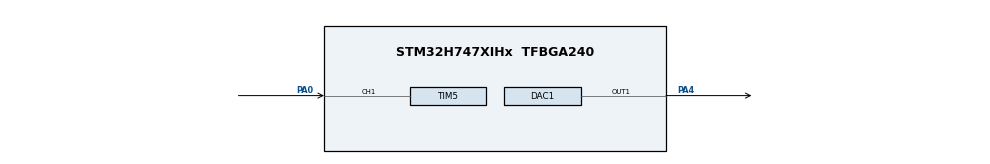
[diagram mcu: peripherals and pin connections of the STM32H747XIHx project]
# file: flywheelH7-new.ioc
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CortexM4.IPs=BDMA,CORTEX_M4\:I,DEBUG,DMA,FATFS_M4\:I,FREERTOS_M4\:I,GPIO,IWDG2\:I,MDMA,NVIC2\:I,OPENAMP_M4\:I,PDM2PCM_M4\:I,PWR,RCC,RESMGR_UTILITY,SYS_M4\:I,USB_DEVICE_M4\:I,USB_HOST_M4\:I,VREFBUF,WWDG2\:I
CortexM7.IPs=BDMA\:I,CORTEX_M7\:I,DEBUG\:I,DMA\:I,FATFS_M7\:I,FREERTOS_M7\:I,GPIO\:I,IWDG1\:I,MDMA\:I,NVIC1\:I,OPENAMP_M7\:I,PDM2PCM_M7\:I,PWR\:I,RCC\:I,RESMGR_UTILITY\:I,SYS\:I,USB_DEVICE_M7\:I,USB_HOST_M7\:I,VREFBUF\:I,WWDG1\:I,DAC1\:I,TIM2\:I,TIM5\:I
DAC1.DAC_Channel-DAC_OUT1=DAC_CHANNEL_1
Mcu.Family=STM32H7
Mcu.Name=STM32H747XIHx
Mcu.Package=TFBGA240
NVIC1.PriorityGroup=NVIC_PRIORITYGROUP_4
NVIC1.TIM5_IRQn=true\:0\:0\:false\:false\:true\:true\:true\:true
NVIC2.PriorityGroup=NVIC_PRIORITYGROUP_4
PA0.PinAttribute=CortexM7
PA0.Signal=S_TIM5_CH1
PA4.PinAttribute=CortexM7
PA4.Signal=COMP_DAC11_group
PH0-OSC_IN\ (PH0).Mode=HSE-External-Oscillator
PH0-OSC_IN\ (PH0).PinAttribute=Free
PH0-OSC_IN\ (PH0).Signal=RCC_OSC_IN
PH1-OSC_OUT\ (PH1).Mode=HSE-External-Oscillator
PH1-OSC_OUT\ (PH1).PinAttribute=Free
PH1-OSC_OUT\ (PH1).Signal=RCC_OSC_OUT
ProjectManager.HeapSize=M4-0x200,M7-0x200
ProjectManager.StackSize=M4-0x400,M7-0x400
ProjectManager.TargetToolchain=STM32CubeIDE
RCC.ADCFreq_Value=50390625
RCC.APB1Freq_Value=100000000
RCC.APB2Freq_Value=100000000
RCC.APB3Freq_Value=100000000
RCC.APB4Freq_Value=100000000
RCC.CortexFreq_Value=400000000
RCC.D1PPRE=RCC_APB3_DIV2
RCC.D2PPRE1=RCC_APB1_DIV2
RCC.D2PPRE2=RCC_APB2_DIV2
RCC.D3PPRE=RCC_APB4_DIV2
RCC.DIVM1=2
RCC.DIVN1=64
RCC.HCLKFreq_Value=200000000
RCC.HPRE=RCC_HCLK_DIV2
RCC.PLL2FRACN=0
RCC.PLL3FRACN=0
RCC.PLLFRACN=0
RCC.PLLSourceVirtual=RCC_PLLSOURCE_HSE
RCC.SYSCLKFreq_VALUE=400000000
RCC.SYSCLKSource=RCC_SYSCLKSOURCE_PLLCLK
RCC.USART16CLockSelection=RCC_USART16CLKSOURCE_CSI
RCC.USBCLockSelection=RCC_USBCLKSOURCE_HSI48
RCC.USBFreq_Value=48000000
SH.COMP_DAC11_group.0=DAC1_OUT1,DAC_OUT1
SH.S_TIM5_CH1.0=TIM5_CH1,Input_Capture1_from_TI1
SYS.userName=SYS_M7
TIM5.Channel-Input_Capture1_from_TI1=TIM_CHANNEL_1
VP_SYS_M4_VS_Systick.Mode=SysTick
VP_TIM2_VS_ClockSourceINT.Mode=Internal
VP_TIM5_VS_ClockSourceINT.Mode=Internal
board=custom

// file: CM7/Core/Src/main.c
/* USER CODE BEGIN Header */
/**
  ******************************************************************************
  * @file           : main.c
  * @brief          : Main program body
  ******************************************************************************
  * @attention
  *
  * Copyright (c) 2023 STMicroelectronics.
  * All rights reserved.
  *
  * This software is licensed under terms that can be found in the LICENSE file
  * in the root directory of this software component.
  * If no LICENSE file comes with this software, it is provided AS-IS.
  *
  ******************************************************************************
  */
/* USER CODE END Header */
#include "main.h"

/* USER CODE BEGIN Includes */
#include <stdio.h>
#include <math.h>
#include<arm_math.h>
//#include "retarget.h"

/* USER CODE END Includes */

/* USER CODE BEGIN PD */

#ifndef HSEM_ID_0
#define HSEM_ID_0 (0U) /* HW semaphore 0*/
#endif
/* USER CODE END PD */

DAC_HandleTypeDef hdac1;

TIM_HandleTypeDef htim2;
TIM_HandleTypeDef htim5;

/* USER CODE BEGIN PV */
#define FFT_BUFFER_SIZE 256
#define SAMPLE_SIZE 113
#define NUM_FIRINGS 3

struct Result {
	float amplitude;
	float phase;
};

uint8_t done1 = 0;
uint8_t revs = 0;

float radians [SAMPLE_SIZE]; //changed from 258 to 129

float freq = 0;

float phase_data[200];

uint8_t phase_index = 0;

float timee2 = 0;

float radianAvg = 0;

float third_harmonic_ampl = 0;

float third_harmonic_phase = 0;

struct Result results;

//float resultantAngularAcc = 0;
//float total = 0;
//float radianAvg;
//float rate;

arm_rfft_fast_instance_f32 fftHandler;

float fftBufIn[FFT_BUFFER_SIZE];
float fftBufOut[FFT_BUFFER_SIZE];

float fftResult[FFT_BUFFER_SIZE/2];

//char radianStr[9];
/* USER CODE END PV */

void SystemClock_Config(void);
static void MX_GPIO_Init(void);
static void MX_DAC1_Init(void);
static void MX_TIM2_Init(void);
static void MX_TIM5_Init(void);
/* USER CODE BEGIN PFP */

struct Result fftCalc(float rad[SAMPLE_SIZE]);

uint16_t dacOut(float out);
/* USER CODE END PFP */

int main(void)
{
/* USER CODE BEGIN Boot_Mode_Sequence_0 */
  int32_t timeout;
/* USER CODE END Boot_Mode_Sequence_0 */

  /* Enable I-Cache---------------------------------------------------------*/
  SCB_EnableICache();

  /* Enable D-Cache---------------------------------------------------------*/
  SCB_EnableDCache();

/* USER CODE BEGIN Boot_Mode_Sequence_1 */
  /* Wait until CPU2 boots and enters in stop mode or timeout*/

  timeout = 0xFFFF;
 while((__HAL_RCC_GET_FLAG(RCC_FLAG_D2CKRDY) != RESET) && (timeout-- > 0));
 if ( timeout < 0 )
 {
 Error_Handler();
 }

/* USER CODE END Boot_Mode_Sequence_1 */
  /* MCU Configuration--------------------------------------------------------*/

  /* Reset of all peripherals, Initializes the Flash interface and the Systick. */
  HAL_Init();

  /* Configure the system clock */
  SystemClock_Config();
/* USER CODE BEGIN Boot_Mode_Sequence_2 */
/* When system initialization is finished, Cortex-M7 will release Cortex-M4 by means of
HSEM notification */
/*HW semaphore Clock enable*/
__HAL_RCC_HSEM_CLK_ENABLE();
/*Take HSEM */
HAL_HSEM_FastTake(HSEM_ID_0);
/*Release HSEM in order to notify the CPU2(CM4)*/
HAL_HSEM_Release(HSEM_ID_0,0);
/* wait until CPU2 wakes up from stop mode */
timeout = 0xFFFF;
while((__HAL_RCC_GET_FLAG(RCC_FLAG_D2CKRDY) == RESET) && (timeout-- > 0));
if ( timeout < 0 )
{
Error_Handler();
}
/* USER CODE END Boot_Mode_Sequence_2 */

  /* Initialize all configured peripherals */
  MX_GPIO_Init();
  MX_DAC1_Init();
  MX_TIM2_Init();
  MX_TIM5_Init();
  /* USER CODE BEGIN 2 */
  arm_rfft_fast_init_f32(&fftHandler, FFT_BUFFER_SIZE);
HAL_DAC_Start(&hdac1,DAC_CHANNEL_1);
  HAL_DAC_SetValue(&hdac1, DAC_CHANNEL_1,DAC_ALIGN_12B_R,0);
  TIM5->CNT = 0;
  HAL_TIM_IC_Start_IT(&htim5, TIM_CHANNEL_1);
    TIM2->CNT = 0;
  HAL_TIM_Base_Start(&htim2);

  //printf("start");

  /* USER CODE END 2 */

  /* Infinite loop */
  /* USER CODE BEGIN WHILE */
  while (1)
  {

    if(done1 ==1){

      TIM2->CNT = 0;

      struct Result results = fftCalc(radians);

      timee2 = TIM2->CNT/200;
      third_harmonic_ampl = results.amplitude;

      third_harmonic_phase = results.phase;

      revs = revs + 1;

//      phase_data[phase_index] = third_harmonic_phase;
      uint16_t finalOut = dacOut(results.amplitude);

//      phase_index = phase_index + 1;
//      TIM2->CNT = 0;

      done1 = 0;

    //TIM5->CNT = 0;//Resets counter

    //HAL_TIM_IC_Start_IT(&htim5, TIM_CHANNEL_1);
    }
    /* USER CODE END WHILE */

  }
}

void SystemClock_Config(void)
{
  RCC_OscInitTypeDef RCC_OscInitStruct = {0};
  RCC_ClkInitTypeDef RCC_ClkInitStruct = {0};

  /** Supply configuration update enable
  */
  HAL_PWREx_ConfigSupply(PWR_DIRECT_SMPS_SUPPLY);

  /** Configure the main internal regulator output voltage
  */
  __HAL_PWR_VOLTAGESCALING_CONFIG(PWR_REGULATOR_VOLTAGE_SCALE1);

  while(!__HAL_PWR_GET_FLAG(PWR_FLAG_VOSRDY)) {}

  /** Initializes the RCC Oscillators according to the specified parameters
  * in the RCC_OscInitTypeDef structure.
  */
  RCC_OscInitStruct.OscillatorType = RCC_OSCILLATORTYPE_HSE;
  RCC_OscInitStruct.HSEState = RCC_HSE_ON;
  RCC_OscInitStruct.PLL.PLLState = RCC_PLL_ON;
  RCC_OscInitStruct.PLL.PLLSource = RCC_PLLSOURCE_HSE;
  RCC_OscInitStruct.PLL.PLLM = 2;
  RCC_OscInitStruct.PLL.PLLN = 64;
  RCC_OscInitStruct.PLL.PLLP = 2;
  RCC_OscInitStruct.PLL.PLLQ = 2;
  RCC_OscInitStruct.PLL.PLLR = 2;
  RCC_OscInitStruct.PLL.PLLRGE = RCC_PLL1VCIRANGE_3;
  RCC_OscInitStruct.PLL.PLLVCOSEL = RCC_PLL1VCOWIDE;
  RCC_OscInitStruct.PLL.PLLFRACN = 0;
  if (HAL_RCC_OscConfig(&RCC_OscInitStruct) != HAL_OK)
  {
    Error_Handler();
  }

  /** Initializes the CPU, AHB and APB buses clocks
  */
  RCC_ClkInitStruct.ClockType = RCC_CLOCKTYPE_HCLK|RCC_CLOCKTYPE_SYSCLK
                              |RCC_CLOCKTYPE_PCLK1|RCC_CLOCKTYPE_PCLK2
                              |RCC_CLOCKTYPE_D3PCLK1|RCC_CLOCKTYPE_D1PCLK1;
  RCC_ClkInitStruct.SYSCLKSource = RCC_SYSCLKSOURCE_PLLCLK;
  RCC_ClkInitStruct.SYSCLKDivider = RCC_SYSCLK_DIV1;
  RCC_ClkInitStruct.AHBCLKDivider = RCC_HCLK_DIV2;
  RCC_ClkInitStruct.APB3CLKDivider = RCC_APB3_DIV2;
  RCC_ClkInitStruct.APB1CLKDivider = RCC_APB1_DIV2;
  RCC_ClkInitStruct.APB2CLKDivider = RCC_APB2_DIV2;
  RCC_ClkInitStruct.APB4CLKDivider = RCC_APB4_DIV2;

  if (HAL_RCC_ClockConfig(&RCC_ClkInitStruct, FLASH_LATENCY_2) != HAL_OK)
  {
    Error_Handler();
  }
}

static void MX_DAC1_Init(void)
{

  DAC_ChannelConfTypeDef sConfig = {0};

  /** DAC Initialization
  */
  hdac1.Instance = DAC1;
  if (HAL_DAC_Init(&hdac1) != HAL_OK)
  {
    Error_Handler();
  }

  /** DAC channel OUT1 config
  */
  sConfig.DAC_SampleAndHold = DAC_SAMPLEANDHOLD_DISABLE;
  sConfig.DAC_Trigger = DAC_TRIGGER_NONE;
  sConfig.DAC_OutputBuffer = DAC_OUTPUTBUFFER_ENABLE;
  sConfig.DAC_ConnectOnChipPeripheral = DAC_CHIPCONNECT_DISABLE;
  sConfig.DAC_UserTrimming = DAC_TRIMMING_FACTORY;
  if (HAL_DAC_ConfigChannel(&hdac1, &sConfig, DAC_CHANNEL_1) != HAL_OK)
  {
    Error_Handler();
  }

}

static void MX_TIM2_Init(void)
{

  TIM_ClockConfigTypeDef sClockSourceConfig = {0};
  TIM_MasterConfigTypeDef sMasterConfig = {0};

  htim2.Instance = TIM2;
  htim2.Init.Prescaler = 0;
  htim2.Init.CounterMode = TIM_COUNTERMODE_UP;
  htim2.Init.Period = 4294967295;
  htim2.Init.ClockDivision = TIM_CLOCKDIVISION_DIV1;
  htim2.Init.AutoReloadPreload = TIM_AUTORELOAD_PRELOAD_DISABLE;
  if (HAL_TIM_Base_Init(&htim2) != HAL_OK)
  {
    Error_Handler();
  }
  sClockSourceConfig.ClockSource = TIM_CLOCKSOURCE_INTERNAL;
  if (HAL_TIM_ConfigClockSource(&htim2, &sClockSourceConfig) != HAL_OK)
  {
    Error_Handler();
  }
  sMasterConfig.MasterOutputTrigger = TIM_TRGO_RESET;
  sMasterConfig.MasterSlaveMode = TIM_MASTERSLAVEMODE_DISABLE;
  if (HAL_TIMEx_MasterConfigSynchronization(&htim2, &sMasterConfig) != HAL_OK)
  {
    Error_Handler();
  }

}

static void MX_TIM5_Init(void)
{

  TIM_ClockConfigTypeDef sClockSourceConfig = {0};
  TIM_MasterConfigTypeDef sMasterConfig = {0};
  TIM_IC_InitTypeDef sConfigIC = {0};

  htim5.Instance = TIM5;
  htim5.Init.Prescaler = 0;
  htim5.Init.CounterMode = TIM_COUNTERMODE_UP;
  htim5.Init.Period = 4294967295;
  htim5.Init.ClockDivision = TIM_CLOCKDIVISION_DIV1;
  htim5.Init.AutoReloadPreload = TIM_AUTORELOAD_PRELOAD_DISABLE;
  if (HAL_TIM_Base_Init(&htim5) != HAL_OK)
  {
    Error_Handler();
  }
  sClockSourceConfig.ClockSource = TIM_CLOCKSOURCE_INTERNAL;
  if (HAL_TIM_ConfigClockSource(&htim5, &sClockSourceConfig) != HAL_OK)
  {
    Error_Handler();
  }
  if (HAL_TIM_IC_Init(&htim5) != HAL_OK)
  {
    Error_Handler();
  }
  sMasterConfig.MasterOutputTrigger = TIM_TRGO_RESET;
  sMasterConfig.MasterSlaveMode = TIM_MASTERSLAVEMODE_DISABLE;
  if (HAL_TIMEx_MasterConfigSynchronization(&htim5, &sMasterConfig) != HAL_OK)
  {
    Error_Handler();
  }
  sConfigIC.ICPolarity = TIM_INPUTCHANNELPOLARITY_RISING;
  sConfigIC.ICSelection = TIM_ICSELECTION_DIRECTTI;
  sConfigIC.ICPrescaler = TIM_ICPSC_DIV1;
  sConfigIC.ICFilter = 0;
  if (HAL_TIM_IC_ConfigChannel(&htim5, &sConfigIC, TIM_CHANNEL_1) != HAL_OK)
  {
    Error_Handler();
  }

}

static void MX_GPIO_Init(void)
{

  /* GPIO Ports Clock Enable */
  __HAL_RCC_GPIOH_CLK_ENABLE();
  __HAL_RCC_GPIOA_CLK_ENABLE();

}

/* USER CODE BEGIN 4 */

uint16_t dacOut(float out){

  uint16_t outThis =(out - 0) * (4095 - 0) / (2000 - 0) + 0; //  (x - in_min) * (out_max - out_min) / (in_max - in_min) + out_min;
  HAL_DAC_SetValue(&hdac1, DAC_CHANNEL_1, DAC_ALIGN_12B_R, outThis);
  return(outThis);

}

struct Result fftCalc(float radFFT [SAMPLE_SIZE]){

	float total = 0;
////	uint8_t fftIndex = 0;

	float rate = (radFFT[112] - radFFT[0]) / SAMPLE_SIZE;
	         for ( int j = 0; j < SAMPLE_SIZE; j++) { // for loop to add all the 113 values

	        	 radFFT[j] = radFFT[j] - j * rate;

	        	 total += radFFT[j];

	         }

	        radianAvg = total / SAMPLE_SIZE; // to get the average of 113 values (1 revs)
//
	         memset(fftBufIn, 0, FFT_BUFFER_SIZE*sizeof(float));

	         for ( int o = 0; o < SAMPLE_SIZE; o++) { // for loop to add all the 113 values to the array
	      	        fftBufIn[o] = radFFT[o] - radianAvg;
//	      	        if (o >= 114) {
//	      	        	fftBufIn[o-1] = 0;
//	      	        }
	      	         }
	         arm_rfft_fast_f32(&fftHandler,fftBufIn, fftBufOut,0);

	         results.amplitude = sqrtf(((fftBufOut[14]) * (fftBufOut[14])) + ((fftBufOut[15]) * (fftBufOut[15]))) * 2 * NUM_FIRINGS/113 * radianAvg; // 6/113 = 0.05309 and 14 is real and 15 is imag

	         results.phase = atan2(fftBufOut[15], fftBufOut[14])  * 57.2958; //conversion from radians to degrees

//	         arm_cmplx_mag_f32(fftBufOut, fftResult, FFT_BUFFER_SIZE/2);
	         memset(fftBufIn, 0x00, FFT_BUFFER_SIZE*sizeof(float));
	         memset(fftBufOut, 0x00, FFT_BUFFER_SIZE*sizeof(float));

	         return results;
}

/* USER CODE END 4 */

void Error_Handler(void)
{
  __disable_irq();
  while (1)
  {
  }
}
